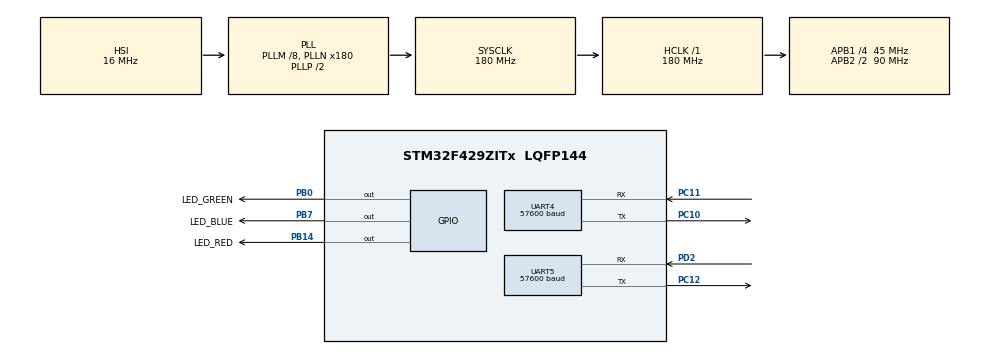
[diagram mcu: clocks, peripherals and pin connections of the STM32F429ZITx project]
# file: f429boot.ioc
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Mcu.Family=STM32F4
Mcu.Name=STM32F429ZITx
Mcu.Package=LQFP144
NVIC.PriorityGroup=NVIC_PRIORITYGROUP_4
NVIC.TIM7_IRQn=true\:15\:0\:false\:false\:true\:false\:true\:true
NVIC.TimeBase=TIM7_IRQn
NVIC.TimeBaseIP=TIM7
NVIC.UART4_IRQn=true\:0\:0\:false\:false\:true\:true\:true\:true
NVIC.UART5_IRQn=true\:0\:0\:false\:false\:true\:true\:true\:true
PB0.GPIO_Label=LED_GREEN
PB0.Signal=GPIO_Output
PB14.GPIO_Label=LED_RED
PB14.Signal=GPIO_Output
PB7.GPIO_Label=LED_BLUE
PB7.Signal=GPIO_Output
PC10.Mode=Asynchronous
PC10.Signal=UART4_TX
PC11.Mode=Asynchronous
PC11.Signal=UART4_RX
PC12.Mode=Asynchronous
PC12.Signal=UART5_TX
PD2.Mode=Asynchronous
PD2.Signal=UART5_RX
ProjectManager.HeapSize=0x200
ProjectManager.StackSize=0x400
ProjectManager.TargetToolchain=Makefile
RCC.48MHZClocksFreq_Value=90000000
RCC.AHBFreq_Value=180000000
RCC.APB1CLKDivider=RCC_HCLK_DIV4
RCC.APB1Freq_Value=45000000
RCC.APB1TimFreq_Value=90000000
RCC.APB2CLKDivider=RCC_HCLK_DIV2
RCC.APB2Freq_Value=90000000
RCC.APB2TimFreq_Value=180000000
RCC.CortexFreq_Value=180000000
RCC.HCLKFreq_Value=180000000
RCC.HSE_VALUE=25000000
RCC.HSI_VALUE=16000000
RCC.LSE_VALUE=32768
RCC.PLLM=8
RCC.PLLN=180
RCC.SYSCLKFreq_VALUE=180000000
RCC.SYSCLKSource=RCC_SYSCLKSOURCE_PLLCLK
RCC.VCOOutputFreq_Value=360000000
UART4.BaudRate=57600
UART4.VirtualMode=Asynchronous
UART5.BaudRate=57600
UART5.VirtualMode=Asynchronous
VP_CRC_VS_CRC.Mode=CRC_Activate
VP_SYS_VS_tim7.Mode=TIM7
board=custom

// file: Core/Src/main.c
/* USER CODE BEGIN Header */
/**
  ******************************************************************************
  * @file           : main.c
  * @brief          : Main program body
  ******************************************************************************
  * @attention
  *
  * Copyright (c) 2022 STMicroelectronics.
  * All rights reserved.
  *
  * This software is licensed under terms that can be found in the LICENSE file
  * in the root directory of this software component.
  * If no LICENSE file comes with this software, it is provided AS-IS.
  *
  ******************************************************************************
  */
/* USER CODE END Header */
#include "main.h"
#include "crc.h"
#include "usart.h"
#include "gpio.h"

/* USER CODE BEGIN Includes */
#include "bootloader.h"
/* USER CODE END Includes */

void SystemClock_Config(void);

int main(void)
{

  /* MCU Configuration--------------------------------------------------------*/

  /* Reset of all peripherals, Initializes the Flash interface and the Systick. */
  HAL_Init();

  /* Configure the system clock */
  SystemClock_Config();

  /* Initialize all configured peripherals */
  MX_GPIO_Init();
  MX_CRC_Init();
  MX_UART4_Init();
  MX_UART5_Init();
  /* USER CODE BEGIN 2 */
  LED_RED_ON(); LED_BLUE_ON(); LED_GREEN_ON();
  HAL_Delay(100);
  LED_RED_OFF(); LED_BLUE_OFF(); LED_GREEN_OFF();
  /* USER CODE END 2 */

  /* Infinite loop */
  /* USER CODE BEGIN WHILE */
  while (1)
  {
    Bootloader_Process();
    /* USER CODE END WHILE */

  }
}

void SystemClock_Config(void)
{
  RCC_OscInitTypeDef RCC_OscInitStruct = {0};
  RCC_ClkInitTypeDef RCC_ClkInitStruct = {0};

  /** Configure the main internal regulator output voltage
  */
  __HAL_RCC_PWR_CLK_ENABLE();
  __HAL_PWR_VOLTAGESCALING_CONFIG(PWR_REGULATOR_VOLTAGE_SCALE1);

  /** Initializes the RCC Oscillators according to the specified parameters
  * in the RCC_OscInitTypeDef structure.
  */
  RCC_OscInitStruct.OscillatorType = RCC_OSCILLATORTYPE_HSI;
  RCC_OscInitStruct.HSIState = RCC_HSI_ON;
  RCC_OscInitStruct.HSICalibrationValue = RCC_HSICALIBRATION_DEFAULT;
  RCC_OscInitStruct.PLL.PLLState = RCC_PLL_ON;
  RCC_OscInitStruct.PLL.PLLSource = RCC_PLLSOURCE_HSI;
  RCC_OscInitStruct.PLL.PLLM = 8;
  RCC_OscInitStruct.PLL.PLLN = 180;
  RCC_OscInitStruct.PLL.PLLP = RCC_PLLP_DIV2;
  RCC_OscInitStruct.PLL.PLLQ = 4;
  if (HAL_RCC_OscConfig(&RCC_OscInitStruct) != HAL_OK)
  {
    Error_Handler();
  }

  /** Activate the Over-Drive mode
  */
  if (HAL_PWREx_EnableOverDrive() != HAL_OK)
  {
    Error_Handler();
  }

  /** Initializes the CPU, AHB and APB buses clocks
  */
  RCC_ClkInitStruct.ClockType = RCC_CLOCKTYPE_HCLK|RCC_CLOCKTYPE_SYSCLK
                              |RCC_CLOCKTYPE_PCLK1|RCC_CLOCKTYPE_PCLK2;
  RCC_ClkInitStruct.SYSCLKSource = RCC_SYSCLKSOURCE_PLLCLK;
  RCC_ClkInitStruct.AHBCLKDivider = RCC_SYSCLK_DIV1;
  RCC_ClkInitStruct.APB1CLKDivider = RCC_HCLK_DIV4;
  RCC_ClkInitStruct.APB2CLKDivider = RCC_HCLK_DIV2;

  if (HAL_RCC_ClockConfig(&RCC_ClkInitStruct, FLASH_LATENCY_5) != HAL_OK)
  {
    Error_Handler();
  }
}

void HAL_TIM_PeriodElapsedCallback(TIM_HandleTypeDef *htim)
{
  if (htim->Instance == TIM7) {
    HAL_IncTick();
  }
}

void Error_Handler(void)
{
  __disable_irq();
  while (1)
  {
  }
}
